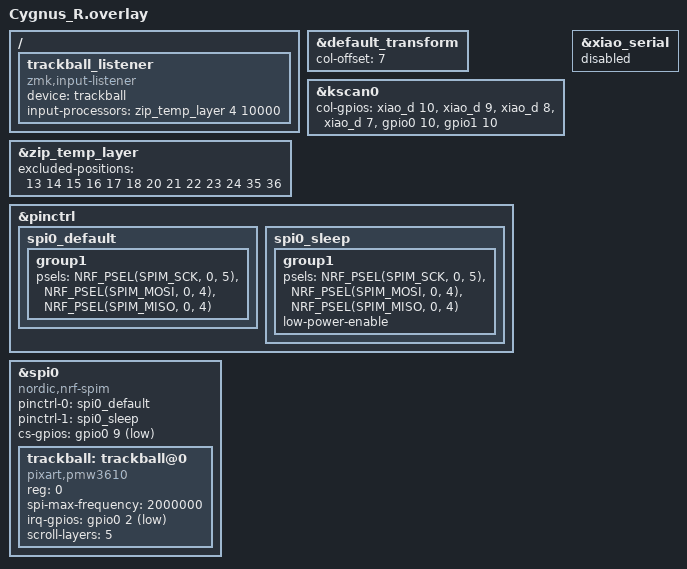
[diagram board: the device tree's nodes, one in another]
#include "Cygnus.dtsi"
#include <input/processors.dtsi>

&default_transform {
    col-offset = <7>;
};

&kscan0 {
        col-gpios
            = <&xiao_d 10 GPIO_ACTIVE_HIGH>
            , <&xiao_d 9 GPIO_ACTIVE_HIGH> 
            , <&xiao_d 8 GPIO_ACTIVE_HIGH> 
            , <&xiao_d 7 GPIO_ACTIVE_HIGH> 
            , <&gpio0 10 GPIO_ACTIVE_HIGH>
            , <&gpio1 10 GPIO_ACTIVE_HIGH>
            ;
};

/ {
    trackball_listener {
        compatible = "zmk,input-listener";
        device = <&trackball>;

        input-processors = <&zip_temp_layer 4 10000>;
    };
};

// MOUSE layer (4) positions that should stay active while clicking/holding,
// so they don't immediately kick the auto-mouse-layer back out:
// 13 A, 14 S, 15 D, 16 F, 17 G, 18 MCLK, 20 H, 21 J, 22 K, 23 L, 24 MINUS,
// 35 M, 36 COMMA (see MOUSE layer bindings in Cygnus.keymap)
&zip_temp_layer {
    excluded-positions = <13 14 15 16 17 18 20 21 22 23 24 35 36>;
};

&pinctrl {
    spi0_default: spi0_default {
        group1 {
            psels = <NRF_PSEL(SPIM_SCK, 0, 5)>,
                <NRF_PSEL(SPIM_MOSI, 0, 4)>,
                <NRF_PSEL(SPIM_MISO, 0, 4)>;
        };
    };

    spi0_sleep: spi0_sleep {
        group1 {
            psels = <NRF_PSEL(SPIM_SCK, 0, 5)>,
                <NRF_PSEL(SPIM_MOSI, 0, 4)>,
                <NRF_PSEL(SPIM_MISO, 0, 4)>;
            low-power-enable;
        };
    };
};

&xiao_serial { status = "disabled"; };

&spi0 {
    status = "okay";
    compatible = "nordic,nrf-spim";
    pinctrl-0 = <&spi0_default>;
    pinctrl-1 = <&spi0_sleep>;
    pinctrl-names = "default", "sleep";
    cs-gpios = <&gpio0 9 GPIO_ACTIVE_LOW>;

    trackball: trackball@0 {
        status = "okay";
        compatible = "pixart,pmw3610";
        reg = <0>;
        spi-max-frequency = <2000000>;
        irq-gpios = <&gpio0 2 (GPIO_ACTIVE_LOW | GPIO_PULL_UP)>;
        scroll-layers = <5>;
    };
};


